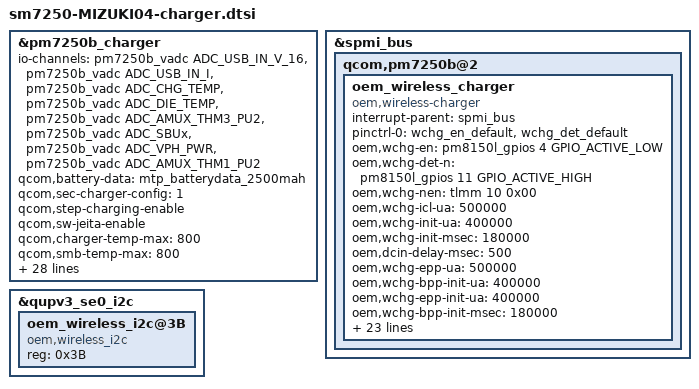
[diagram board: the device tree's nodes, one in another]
/*
 * This software is contributed or developed by KYOCERA Corporation.
 * (C) 2020 KYOCERA Corporation
 *
 * This program is free software; you can redistribute it and/or modify
 * it under the terms of the GNU General Public License version 2 and
 * only version 2 as published by the Free Software Foundation.
 *
 * This program is distributed in the hope that it will be useful,
 * but WITHOUT ANY WARRANTY; without even the implied warranty of
 * MERCHANTABILITY or FITNESS FOR A PARTICULAR PURPOSE.  See the
 * GNU General Public License for more details.
 */

#include <dt-bindings/iio/qcom,spmi-vadc.h>

&pm7250b_charger {
	status = "ok";
	io-channels = <&pm7250b_vadc ADC_USB_IN_V_16>,
		      <&pm7250b_vadc ADC_USB_IN_I>,
		      <&pm7250b_vadc ADC_CHG_TEMP>,
		      <&pm7250b_vadc ADC_DIE_TEMP>,
		      <&pm7250b_vadc ADC_AMUX_THM3_PU2>,
		      <&pm7250b_vadc ADC_SBUx>,
		      <&pm7250b_vadc ADC_VPH_PWR>,
		      <&pm7250b_vadc ADC_AMUX_THM1_PU2>;
	io-channel-names = "usb_in_voltage",
			   "usb_in_current",
			   "chg_temp",
			   "die_temp",
			   "conn_temp",
			   "sbux_res",
			   "vph_voltage",
			   "skin_temp";
	qcom,battery-data = <&mtp_batterydata_2500mah>;
	qcom,sec-charger-config = <1>;
	qcom,step-charging-enable;
	qcom,sw-jeita-enable;
	/delete-property/ qcom,lpd-disable;
	qcom,charger-temp-max = <800>;
	qcom,smb-temp-max = <800>;
	qcom,suspend-input-on-debug-batt;
	qcom,fcc-stepping-enable;
	qcom,fcc-step-delay-ms = <100>;
	qcom,fcc-step-size-ua = <100000>;
	qcom,smb-internal-pull-kohm = <0>;
	qcom,en-skin-therm-mitigation;
	qcom,hvdcp3-standalone-config;
	dpdm-supply = <&usb2_phy0>;
	qcom,fcc-max-ua = <2350000>;
	qcom,usb-icl-ua = <1900000>;
	qcom,fv-max-uv = <4380000>;
	qcom,chg-term-src = <1>;
	qcom,chg-term-current-ma = <(-150)>;
	qcom,chg-term-base-current-ma = <150>;
	qcom,auto-recharge-soc = <95>;
	qcom,auto-recharge-vbat-mv = <4180>;
	qcom,thermal-mitigation = <2350000 2200000 2000000 1800000 1600000 1400000 1200000 1000000 800000 600000 400000 200000 0>;
	qcom,hvdcp-disable;
	qcom,otg-cl-ua = <1000000>;
	qcom,wls-current-max-ua = <400000>;

	oem,dcin-current-max-ua = <900000>;
	oem,wls-epp-current-max-ua = <200000>;
	pinctrl-names = "default";
	pinctrl-0 = <&ext_chg_det_default>;
	oem,chg-term-current-ma-wchg = <(-350)>;
	oem,chg-term-base-current-ma-wchg = <350>;
	oem,thermal-limit-level = <8>;
	oem,wchg-disable-thresh = <90>;
};

&spmi_bus {
	qcom,pm7250b@2 {
		oem_wireless_charger {
			compatible = "oem,wireless-charger";
			interrupt-parent = <&spmi_bus>;
			pinctrl-names = "default";
			pinctrl-0 = <&wchg_en_default &wchg_det_default>;
			oem,wchg-en = <&pm8150l_gpios 4 GPIO_ACTIVE_LOW>;
			oem,wchg-det-n = <&pm8150l_gpios 11 GPIO_ACTIVE_HIGH>;
			oem,wchg-nen = <&tlmm 10 0x00>;
			oem,wchg-icl-ua = <500000>;
			oem,wchg-init-ua = <400000>;
			oem,wchg-init-msec = <180000>;
			oem,dcin-delay-msec = <500>;
			oem,wchg-epp-ua = <500000>;
			oem,wchg-bpp-init-ua = <400000>;
			oem,wchg-epp-init-ua = <400000>;
			oem,wchg-bpp-init-msec = <180000>;
			oem,wchg-epp-init-msec = <180000>;
			oem,wchg-offchg-init-msec = <180000>;
			oem,wchg-step-ua = <50000>;
			oem,wchg-step-msec = <1000>;
			oem,wchg-epp-step-ua = <50000>;
			oem,wchg-bpp-step-msec = <1000>;
			oem,wchg-epp-step-msec = <1000>;
			oem,wchg-offchg-step-msec = <1000>;
			oem,wchg-bpp-step-init-ua = <450000>;
			oem,wchg-epp-step-init-ua = <450000>;
			oem,wchg-stable-msec = <60000>;
			oem,cc-cv-threshold-uv = <4370000>;
			oem,cc-cv-threshold-warm-uv = <4190000>;
			oem,jeita-warm-thresh = <431>;
			oem,wchg-cv-ua = <400000>;
			oem,wchg-epp-cv-ua = <500000 500000 500000 400000>;
			oem,wchg-full-ua = <250000>;
			oem,wchg-temp-thresh = <(-60000) 43000>;
			oem,wchg-temp-ua = <500000 500000>;
			oem,wchg-temp-hysteresis = <2000>;
			oem,wchg-stop-temp = <53000>;
			oem,wchg-rechg-temp = <41000>;
		};
	};
};

&qupv3_se0_i2c {
	status = "ok";
	oem_wireless_i2c@3B {
		status = "ok";
		compatible = "oem,wireless_i2c";
		reg = <0x3B>;
	};
};
